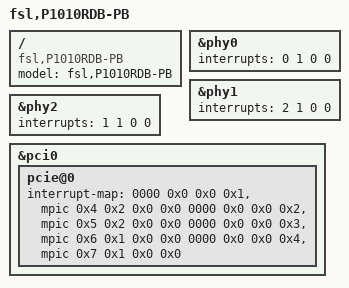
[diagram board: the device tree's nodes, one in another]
// SPDX-License-Identifier: GPL-2.0-or-later
/*
 * P1010 RDB Device Tree Source
 *
 * Copyright 2011 Freescale Semiconductor Inc.
 */

/include/ "p1010si-pre.dtsi"

/ {
	model = "fsl,P1010RDB-PB";
	compatible = "fsl,P1010RDB-PB";

	/include/ "p1010rdb_32b.dtsi"
};

/include/ "p1010rdb.dtsi"

&phy0 {
	interrupts = <0 1 0 0>;
};

&phy1 {
	interrupts = <2 1 0 0>;
};

&phy2 {
	interrupts = <1 1 0 0>;
};

/include/ "p1010si-post.dtsi"

&pci0 {
	pcie@0 {
		interrupt-map = <
			/* IDSEL 0x0 */
			/*
			 *irq[4:5] are active-high
			 *irq[6:7] are active-low
			 */
			0000 0x0 0x0 0x1 &mpic 0x4 0x2 0x0 0x0
			0000 0x0 0x0 0x2 &mpic 0x5 0x2 0x0 0x0
			0000 0x0 0x0 0x3 &mpic 0x6 0x1 0x0 0x0
			0000 0x0 0x0 0x4 &mpic 0x7 0x1 0x0 0x0
			>;
	};
};
